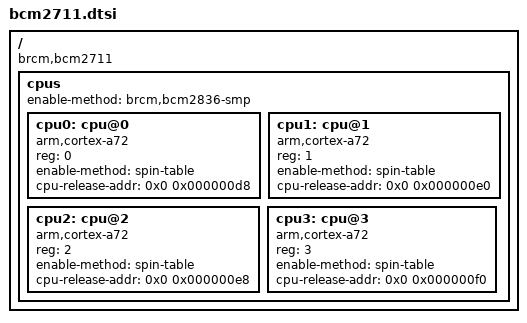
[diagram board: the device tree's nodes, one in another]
/**
 * Copyright (C) 2018 - 2021 bolthur project.
 *
 * This file is part of bolthur/kernel.
 *
 * bolthur/kernel is free software: you can redistribute it and/or modify
 * it under the terms of the GNU General Public License as published by
 * the Free Software Foundation, either version 3 of the License, or
 * (at your option) any later version.
 *
 * bolthur/kernel is distributed in the hope that it will be useful,
 * but WITHOUT ANY WARRANTY; without even the implied warranty of
 * MERCHANTABILITY or FITNESS FOR A PARTICULAR PURPOSE.  See the
 * GNU General Public License for more details.
 *
 * You should have received a copy of the GNU General Public License
 * along with bolthur/kernel.  If not, see <http://www.gnu.org/licenses/>.
 */

/ {
  compatible = "brcm,bcm2711";

  cpus: cpus {
    #address-cells = <1>;
    #size-cells = <0>;
    enable-method = "brcm,bcm2836-smp"; // for ARM 32-bit

    cpu0: cpu@0 {
      device_type = "cpu";
      compatible = "arm,cortex-a72";
      reg = <0>;
      enable-method = "spin-table";
      cpu-release-addr = <0x0 0x000000d8>;
    };

    cpu1: cpu@1 {
      device_type = "cpu";
      compatible = "arm,cortex-a72";
      reg = <1>;
      enable-method = "spin-table";
      cpu-release-addr = <0x0 0x000000e0>;
    };

    cpu2: cpu@2 {
      device_type = "cpu";
      compatible = "arm,cortex-a72";
      reg = <2>;
      enable-method = "spin-table";
      cpu-release-addr = <0x0 0x000000e8>;
    };

    cpu3: cpu@3 {
      device_type = "cpu";
      compatible = "arm,cortex-a72";
      reg = <3>;
      enable-method = "spin-table";
      cpu-release-addr = <0x0 0x000000f0>;
    };
  };
};
